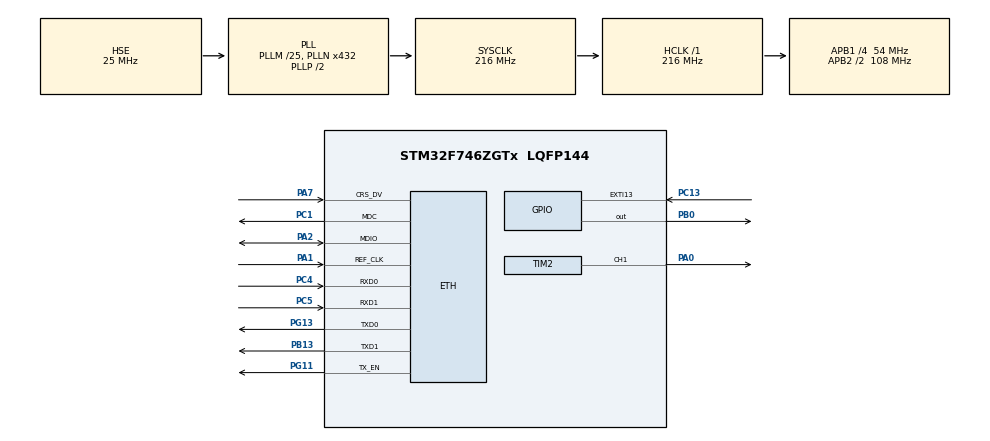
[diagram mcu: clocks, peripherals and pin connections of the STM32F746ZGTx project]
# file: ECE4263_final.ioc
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CORTEX_M7.AccessPermission-Cortex_Memory_Protection_Unit_Region0_Settings=MPU_REGION_FULL_ACCESS
CORTEX_M7.BaseAddress-Cortex_Memory_Protection_Unit_Region0_Settings=0x20010000
CORTEX_M7.CPU_DCache=Enabled
CORTEX_M7.CPU_ICache=Enabled
CORTEX_M7.DisableExec-Cortex_Memory_Protection_Unit_Region0_Settings=MPU_INSTRUCTION_ACCESS_DISABLE
CORTEX_M7.Enable-Cortex_Memory_Protection_Unit_Region0_Settings=MPU_REGION_ENABLE
CORTEX_M7.IsShareable-Cortex_Memory_Protection_Unit_Region0_Settings=MPU_ACCESS_SHAREABLE
CORTEX_M7.MPU_Control=MPU_PRIVILEGED_DEFAULT
CORTEX_M7.PREFETCH_ENABLE=1
CORTEX_M7.Size-Cortex_Memory_Protection_Unit_Region0_Settings=MPU_REGION_SIZE_16KB
CORTEX_M7.TypeExtField-Cortex_Memory_Protection_Unit_Region0_Settings=MPU_TEX_LEVEL1
ETH.MediaInterface=ETH_MEDIA_INTERFACE_RMII
ETH.PhyAddress=0
LWIP.GATEWAY_ADDRESS=192.168.000.001
LWIP.IP_ADDRESS=129.244.042.105
LWIP.LWIP_DHCP=0
LWIP.MEM_SIZE=10*1024
LWIP.NETMASK_ADDRESS=255.255.255.000
LWIP.Version=v2.1.2_Cube
Mcu.Family=STM32F7
Mcu.Name=STM32F746ZGTx
Mcu.Package=LQFP144
NVIC.EXTI15_10_IRQn=true\:0\:0\:false\:false\:true\:true\:true
NVIC.PriorityGroup=NVIC_PRIORITYGROUP_4
PA0/WKUP.Signal=S_TIM2_CH1_ETR
PA1.Mode=RMII
PA1.Signal=ETH_REF_CLK
PA2.Mode=RMII
PA2.Signal=ETH_MDIO
PA7.Mode=RMII
PA7.Signal=ETH_CRS_DV
PB0.Signal=GPIO_Output
PB13.Mode=RMII
PB13.Signal=ETH_TXD1
PC1.Mode=RMII
PC1.Signal=ETH_MDC
PC13.GPIO_ModeDefaultEXTI=GPIO_MODE_IT_FALLING
PC13.GPIO_PuPd=GPIO_NOPULL
PC13.Signal=GPXTI13
PC4.Mode=RMII
PC4.Signal=ETH_RXD0
PC5.Mode=RMII
PC5.Signal=ETH_RXD1
PG11.Mode=RMII
PG11.Signal=ETH_TX_EN
PG13.Mode=RMII
PG13.Signal=ETH_TXD0
PH0/OSC_IN.Mode=HSE-External-Oscillator
PH0/OSC_IN.Signal=RCC_OSC_IN
PH1/OSC_OUT.Mode=HSE-External-Oscillator
PH1/OSC_OUT.Signal=RCC_OSC_OUT
ProjectManager.HeapSize=0x200
ProjectManager.StackSize=0x400
ProjectManager.TargetToolchain=STM32CubeIDE
RCC.AHBFreq_Value=216000000
RCC.APB1CLKDivider=RCC_HCLK_DIV4
RCC.APB1Freq_Value=54000000
RCC.APB1TimFreq_Value=108000000
RCC.APB2CLKDivider=RCC_HCLK_DIV2
RCC.APB2Freq_Value=108000000
RCC.APB2TimFreq_Value=216000000
RCC.CortexFreq_Value=216000000
RCC.HCLKFreq_Value=216000000
RCC.HSE_VALUE=25000000
RCC.HSI_VALUE=16000000
RCC.LSE_VALUE=32768
RCC.PLLM=25
RCC.PLLN=432
RCC.PLLSourceVirtual=RCC_PLLSOURCE_HSE
RCC.PWR_Regulator_Voltage_Scale=PWR_REGULATOR_VOLTAGE_SCALE1
RCC.SYSCLKFreq_VALUE=216000000
RCC.SYSCLKSource=RCC_SYSCLKSOURCE_PLLCLK
RCC.USBFreq_Value=216000000
RCC.VCOOutputFreq_Value=432000000
SH.S_TIM2_CH1_ETR.0=TIM2_CH1,PWM Generation1 CH1
TIM2.Channel-PWM\ Generation1\ CH1=TIM_CHANNEL_1
TIM2.OCMode_PWM-PWM\ Generation1\ CH1=TIM_OCMODE_PWM1
TIM2.Period=2160
TIM2.Prescaler=1000
VP_LWIP_VS_Enabled.Mode=Enabled
VP_TIM2_VS_ClockSourceINT.Mode=Internal
board=custom

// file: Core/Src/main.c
/* USER CODE BEGIN Header */
/**
  ******************************************************************************
  * @file           : main.c
  * @brief          : Main program body
  ******************************************************************************
  * @attention
  *
  * <h2><center>&copy; Copyright (c) 2021 STMicroelectronics.
  * All rights reserved.</center></h2>
  *
  * This software component is licensed by ST under Ultimate Liberty license
  * SLA0044, the "License"; You may not use this file except in compliance with
  * the License. You may obtain a copy of the License at:
  *                             www.st.com/SLA0044
  *
  ******************************************************************************
  */
/* USER CODE END Header */
#include "main.h"
#include "lwip.h"

/* USER CODE BEGIN Includes */

#include "udpClientRAW.h"

/* USER CODE END Includes */

TIM_HandleTypeDef htim2;

void SystemClock_Config(void);
static void MPU_Config(void);
static void MX_GPIO_Init(void);
static void MX_TIM2_Init(void);

/* USER CODE BEGIN 0 */
extern struct netif gnetif;
/* USER CODE END 0 */

int main(void)
{

  /* MPU Configuration--------------------------------------------------------*/
  MPU_Config();

  /* Enable I-Cache---------------------------------------------------------*/
  SCB_EnableICache();

  /* Enable D-Cache---------------------------------------------------------*/
  SCB_EnableDCache();

  /* MCU Configuration--------------------------------------------------------*/

  /* Reset of all peripherals, Initializes the Flash interface and the Systick. */
  HAL_Init();

  /* Configure the system clock */
  SystemClock_Config();

  /* Initialize all configured peripherals */
  MX_GPIO_Init();
  MX_LWIP_Init();
  MX_TIM2_Init();
  /* USER CODE BEGIN 2 */

  // Connect the client to the server
  server_connected = false;
  udpClient_connect();

  // start PWM signal for the servo
  HAL_TIM_PWM_Start(&htim2, TIM_CHANNEL_1);

  /* USER CODE END 2 */

  /* Infinite loop */
  while (1)
  {

    /* USER CODE BEGIN 3 */

    // listen for network events
    ethernetif_input(&gnetif);
    sys_check_timeouts();

  }
  /* USER CODE END 3 */
}

void SystemClock_Config(void)
{
  RCC_OscInitTypeDef RCC_OscInitStruct = {0};
  RCC_ClkInitTypeDef RCC_ClkInitStruct = {0};

  /** Configure the main internal regulator output voltage
  */
  __HAL_RCC_PWR_CLK_ENABLE();
  __HAL_PWR_VOLTAGESCALING_CONFIG(PWR_REGULATOR_VOLTAGE_SCALE1);
  /** Initializes the RCC Oscillators according to the specified parameters
  * in the RCC_OscInitTypeDef structure.
  */
  RCC_OscInitStruct.OscillatorType = RCC_OSCILLATORTYPE_HSE;
  RCC_OscInitStruct.HSEState = RCC_HSE_ON;
  RCC_OscInitStruct.PLL.PLLState = RCC_PLL_ON;
  RCC_OscInitStruct.PLL.PLLSource = RCC_PLLSOURCE_HSE;
  RCC_OscInitStruct.PLL.PLLM = 25;
  RCC_OscInitStruct.PLL.PLLN = 432;
  RCC_OscInitStruct.PLL.PLLP = RCC_PLLP_DIV2;
  RCC_OscInitStruct.PLL.PLLQ = 2;
  if (HAL_RCC_OscConfig(&RCC_OscInitStruct) != HAL_OK)
  {
    Error_Handler();
  }
  /** Activate the Over-Drive mode
  */
  if (HAL_PWREx_EnableOverDrive() != HAL_OK)
  {
    Error_Handler();
  }
  /** Initializes the CPU, AHB and APB buses clocks
  */
  RCC_ClkInitStruct.ClockType = RCC_CLOCKTYPE_HCLK|RCC_CLOCKTYPE_SYSCLK
                              |RCC_CLOCKTYPE_PCLK1|RCC_CLOCKTYPE_PCLK2;
  RCC_ClkInitStruct.SYSCLKSource = RCC_SYSCLKSOURCE_PLLCLK;
  RCC_ClkInitStruct.AHBCLKDivider = RCC_SYSCLK_DIV1;
  RCC_ClkInitStruct.APB1CLKDivider = RCC_HCLK_DIV4;
  RCC_ClkInitStruct.APB2CLKDivider = RCC_HCLK_DIV2;

  if (HAL_RCC_ClockConfig(&RCC_ClkInitStruct, FLASH_LATENCY_7) != HAL_OK)
  {
    Error_Handler();
  }
}

static void MX_TIM2_Init(void)
{

  TIM_ClockConfigTypeDef sClockSourceConfig = {0};
  TIM_MasterConfigTypeDef sMasterConfig = {0};
  TIM_OC_InitTypeDef sConfigOC = {0};

  htim2.Instance = TIM2;
  htim2.Init.Prescaler = 1000;
  htim2.Init.CounterMode = TIM_COUNTERMODE_UP;
  htim2.Init.Period = 2160;
  htim2.Init.ClockDivision = TIM_CLOCKDIVISION_DIV1;
  htim2.Init.AutoReloadPreload = TIM_AUTORELOAD_PRELOAD_DISABLE;
  if (HAL_TIM_Base_Init(&htim2) != HAL_OK)
  {
    Error_Handler();
  }
  sClockSourceConfig.ClockSource = TIM_CLOCKSOURCE_INTERNAL;
  if (HAL_TIM_ConfigClockSource(&htim2, &sClockSourceConfig) != HAL_OK)
  {
    Error_Handler();
  }
  if (HAL_TIM_PWM_Init(&htim2) != HAL_OK)
  {
    Error_Handler();
  }
  sMasterConfig.MasterOutputTrigger = TIM_TRGO_RESET;
  sMasterConfig.MasterSlaveMode = TIM_MASTERSLAVEMODE_DISABLE;
  if (HAL_TIMEx_MasterConfigSynchronization(&htim2, &sMasterConfig) != HAL_OK)
  {
    Error_Handler();
  }
  sConfigOC.OCMode = TIM_OCMODE_PWM1;
  sConfigOC.Pulse = 0;
  sConfigOC.OCPolarity = TIM_OCPOLARITY_HIGH;
  sConfigOC.OCFastMode = TIM_OCFAST_DISABLE;
  if (HAL_TIM_PWM_ConfigChannel(&htim2, &sConfigOC, TIM_CHANNEL_1) != HAL_OK)
  {
    Error_Handler();
  }
  HAL_TIM_MspPostInit(&htim2);

}

static void MX_GPIO_Init(void)
{
  GPIO_InitTypeDef GPIO_InitStruct = {0};

  /* GPIO Ports Clock Enable */
  __HAL_RCC_GPIOC_CLK_ENABLE();
  __HAL_RCC_GPIOH_CLK_ENABLE();
  __HAL_RCC_GPIOA_CLK_ENABLE();
  __HAL_RCC_GPIOB_CLK_ENABLE();
  __HAL_RCC_GPIOG_CLK_ENABLE();

  /*Configure GPIO pin Output Level */
  HAL_GPIO_WritePin(GPIOB, GPIO_PIN_0, GPIO_PIN_RESET);

  /*Configure GPIO pin : PC13 */
  GPIO_InitStruct.Pin = GPIO_PIN_13;
  GPIO_InitStruct.Mode = GPIO_MODE_IT_FALLING;
  GPIO_InitStruct.Pull = GPIO_NOPULL;
  HAL_GPIO_Init(GPIOC, &GPIO_InitStruct);

  /*Configure GPIO pin : PB0 */
  GPIO_InitStruct.Pin = GPIO_PIN_0;
  GPIO_InitStruct.Mode = GPIO_MODE_OUTPUT_PP;
  GPIO_InitStruct.Pull = GPIO_NOPULL;
  GPIO_InitStruct.Speed = GPIO_SPEED_FREQ_LOW;
  HAL_GPIO_Init(GPIOB, &GPIO_InitStruct);

  /* EXTI interrupt init*/
  HAL_NVIC_SetPriority(EXTI15_10_IRQn, 0, 0);
  HAL_NVIC_EnableIRQ(EXTI15_10_IRQn);

}

/* USER CODE BEGIN 4 */
// Argument: integer pulse width in microseconds (1000 to 2000)
void CMD_OPEN_LOCKBOX(void)
{
  htim2.Instance->CCR1 = 25;  // duty cycle is 1.5 ms
  HAL_Delay(800);
  htim2.Instance->CCR1 = 75;  // duty cycle is 1.5 ms
  HAL_Delay(800);
  htim2.Instance->CCR1 = 125;  // duty cycle is 2.5 ms
  HAL_Delay(800);
}
/* USER CODE END 4 */

/* MPU Configuration */

void MPU_Config(void)
{
  MPU_Region_InitTypeDef MPU_InitStruct = {0};

  /* Disables the MPU */
  HAL_MPU_Disable();
  /** Initializes and configures the Region and the memory to be protected
  */
  MPU_InitStruct.Enable = MPU_REGION_ENABLE;
  MPU_InitStruct.Number = MPU_REGION_NUMBER0;
  MPU_InitStruct.BaseAddress = 0x20010000;
  MPU_InitStruct.Size = MPU_REGION_SIZE_16KB;
  MPU_InitStruct.SubRegionDisable = 0x0;
  MPU_InitStruct.TypeExtField = MPU_TEX_LEVEL1;
  MPU_InitStruct.AccessPermission = MPU_REGION_FULL_ACCESS;
  MPU_InitStruct.DisableExec = MPU_INSTRUCTION_ACCESS_DISABLE;
  MPU_InitStruct.IsShareable = MPU_ACCESS_SHAREABLE;
  MPU_InitStruct.IsCacheable = MPU_ACCESS_NOT_CACHEABLE;
  MPU_InitStruct.IsBufferable = MPU_ACCESS_NOT_BUFFERABLE;

  HAL_MPU_ConfigRegion(&MPU_InitStruct);
  /* Enables the MPU */
  HAL_MPU_Enable(MPU_PRIVILEGED_DEFAULT);

}

void Error_Handler(void)
{
  __disable_irq();
  while (1)
  {
  }
}

/************************ (C) COPYRIGHT STMicroelectronics *****END OF FILE****/
